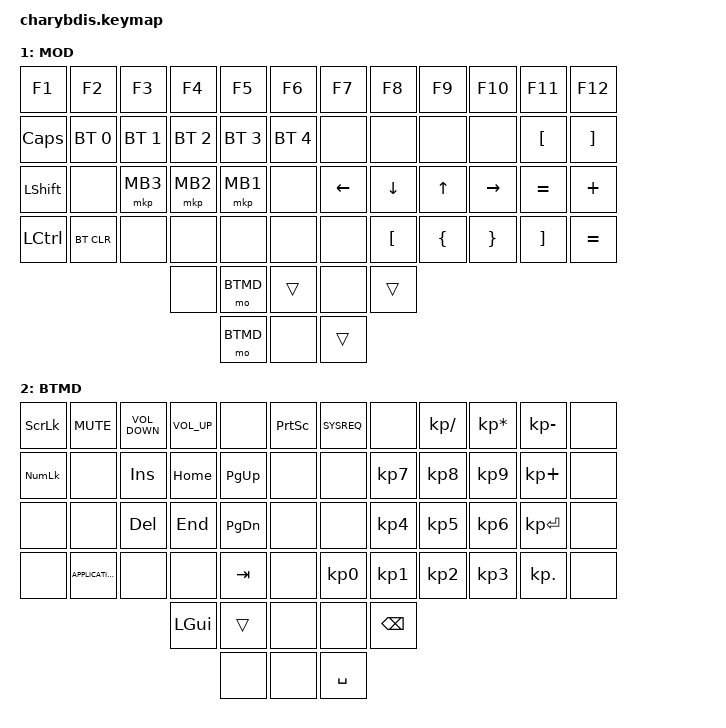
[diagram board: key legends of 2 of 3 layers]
#include <dt-bindings/zmk/mouse.h>
#include <behaviors/mouse_keys.dtsi>
#include <behaviors.dtsi>
#include <dt-bindings/zmk/bt.h>
#include <dt-bindings/zmk/keys.h>
#include <dt-bindings/zmk/pointing.h>
#include "macros.dtsi"

// / {
//     chosen { zmk,matrix_transform = &default_transform; };
// };

/ {
    /* input config for mouse move mode */

    trackball_listener {
        compatible = "zmk,input-behavior-listener";
        device = <&vtrackball>;
        layers = <0 2>;
        evt-type = <INPUT_EV_REL>;
        x-input-code = <INPUT_REL_X>;
        y-input-code = <INPUT_REL_Y>;
        scale-multiplier = <1>;
        scale-divisor = <2>;

        // bindings = <&ib_toggle_layer 7>;
    };

    /* input config for snipe mode */

    trackball_snipe_listener {
        compatible = "zmk,input-behavior-listener";
        device = <&vtrackball>;
        layers = <3>;
        evt-type = <INPUT_EV_REL>;
        x-input-code = <INPUT_REL_X>;
        y-input-code = <INPUT_REL_Y>;
        scale-multiplier = <1>;
        scale-divisor = <4>;
    };

    /* input config for mouse scroll mode */

    trackball_scroll_listener {
        compatible = "zmk,input-behavior-listener";
        device = <&vtrackball>;
        layers = <1>;
        evt-type = <INPUT_EV_REL>;
        x-input-code = <INPUT_REL_MISC>;
        y-input-code = <INPUT_REL_WHEEL>;
        scale-multiplier = <1>;
        scale-divisor = <4>;
        bindings = <&ib_wheel_scaler 1 14>;
    };

    /* define a resolution down scaler only for INPUT_REL_WHEEL */

    ib_wheel_scaler: ib_wheel_scaler {
        compatible = "zmk,input-behavior-scaler";
        #binding-cells = <2>;
        evt-type = <INPUT_EV_REL>;
        input-code = <INPUT_REL_WHEEL>;
    };

    /* adjust cooldown waiting period for mouse key layer after activated */

    ib_toggle_layer: ib_toggle_layer {
        compatible = "zmk,input-behavior-tog-layer";
        #binding-cells = <1>;
        time-to-live-ms = <750>;
    };

    #define DEF 0
#define MOD 1
#define BTMD 2

    behaviors {
        quick_mouse: quick_mouse {
            compatible = "zmk,behavior-hold-tap";
            label = "QUICK_MOUSE";
            bindings = <&mkp>, <&kp>;

            #binding-cells = <2>;
            flavor = "tap-preferred";
            tapping-term-ms = <200>;
            #quick-tap-ms = <200>;
        };
    };

    keymap {
        compatible = "zmk,keymap";

        DEF {
            bindings = <
&kp GRAVE  &kp N1  &kp N2  &kp N3        &kp N4               &kp N5       &kp N6        &kp N7         &kp N8                  &kp N9                   &kp N0    &kp MINUS
&kp TAB    &kp Q   &kp W   &kp E         &kp R                &kp T        &kp Y         &kp U          &kp I                   &kp O                    &kp P     &kp BSLH
&kp ESC    &kp A   &kp S   &kp D         &kp F                &kp G        &kp H         &kp J          &kp K                   &kp L                    &kp SEMI  &kp SQT
&kp LCTRL  &kp Z   &kp X   &kp C         &kp V                &kp B        &kp N         &kp M          &quick_mouse MB1 COMMA  &quick_mouse MB2 PERIOD  &mt LEFT_ALT FSLH  &kp RCTRL
                           &mo MOD       &kp LEFT_SHIFT       &kp LEFT_WIN               &kp LEFT_ALT  &kp BACKSPACE
                                         &kp SPACE            &mt LEFT_ALT DELETE        &kp ENTER &kp LEFT_ALT
            >;
        };

        MOD {
            bindings = <
&kp F1          &kp F2        &kp F3        &kp F4        &kp F5        &kp F6          &kp F7          &kp F8            &kp F9          &kp F10          &kp F11            &kp F12
&kp CAPS        &bt BT_SEL 0  &bt BT_SEL 1  &bt BT_SEL 2  &bt BT_SEL 3  &bt BT_SEL 4    &none           &none             &none           &none            &kp LEFT_BRACKET   &kp RIGHT_BRACKET
&kp LEFT_SHIFT  &none         &mkp MB3      &mkp MB2      &mkp MB1      &none           &kp LEFT_ARROW  &kp DOWN_ARROW    &kp UP_ARROW    &kp RIGHT        &kp EQUAL          &kp PLUS
&kp LCTRL       &bt BT_CLR    &none         &none         &none         &none           &none           &kp LEFT_BRACKET  &kp LEFT_BRACE  &kp RIGHT_BRACE  &kp RIGHT_BRACKET  &kp EQUAL
                                            &none         &mo BTMD      &trans          &none           &trans
                                                          &mo BTMD      &none           &trans
            >;

            sensor-bindings = <&inc_dec_kp C_VOL_UP C_VOL_DN>;
        };

        BTMD {
            bindings = <
&kp SCROLLLOCK  &kp K_MUTE         &kp C_VOLUME_DOWN  &kp C_VOLUME_UP  &none          &kp PRINTSCREEN    &kp SYSREQ       &none            &kp KP_SLASH     &kp KP_ASTERISK  &kp KP_MINUS  &none
&kp KP_NUMLOCK  &none              &kp INSERT         &kp HOME         &kp PAGE_UP    &none              &none            &kp KP_NUMBER_7  &kp KP_NUMBER_8  &kp KP_NUMBER_9  &kp KP_PLUS   &none
&none           &none              &kp DEL            &kp END          &kp PAGE_DOWN  &none              &none            &kp KP_NUMBER_4  &kp KP_NUMBER_5  &kp KP_NUMBER_6  &kp KP_ENTER  &none
&none           &kp K_APPLICATION  &none              &none            &kp TAB        &none              &kp KP_NUMBER_0  &kp KP_NUMBER_1  &kp KP_NUMBER_2  &kp KP_NUMBER_3  &kp KP_DOT    &none
                                                      &kp LEFT_GUI     &trans         &none              &none            &kp BACKSPACE
                                                                       &none          &none              &kp SPACE
            >;
        };
    };
};
